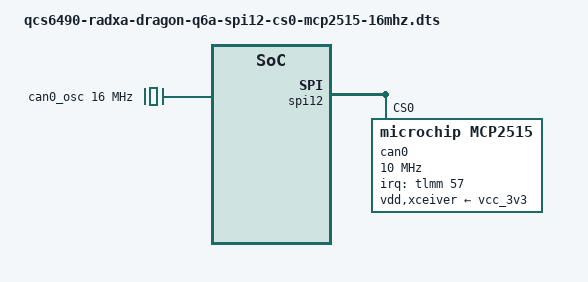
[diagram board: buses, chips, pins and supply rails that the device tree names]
// SPDX-License-Identifier: BSD-3-Clause
//
// Enable MCP2515 SPI CAN controller on SPI12 CS0 with 16 MHz external clock.
// Target: Radxa Dragon Q6A (QCS6490) + Waveshare RS485 CAN HAT (B).
//
// The 16 MHz crystal is the (B)-variant HAT's crystal. The plain
// Waveshare RS485 CAN HAT ships with a 12 MHz crystal post-Aug-2019 and
// must NOT be used on Headwaters: at 500 kbit/s the MCP2515 kernel driver
// cannot achieve the 0.875 sample point with a 12 MHz clock (10/12 TQ =
// 0.833 is the closest reachable), which produced 25–35% RX CRC errors
// in bench and vehicle testing. With 16 MHz the driver hits 14/16 TQ =
// 0.875 exactly and CAN is stable.
//
// 40-pin header mapping (Q6A → same physical pins as RPi's SPI0):
//   pin 19 MOSI → GPIO_49 (SPI12_MOSI)
//   pin 21 MISO → GPIO_48 (SPI12_MISO)
//   pin 23 SCLK → GPIO_50 (SPI12_SCLK)
//   pin 24 CE0  → GPIO_51 (SPI12_CS_0)
//   pin 22 INT  → GPIO_57 (MCP2515 interrupt, falling edge)
//
// Derived from Radxa's upstream DTSO at
//   github.com/radxa-pkg/radxa-overlays
//   arch/arm64/boot/dts/qcom/overlays/
// Vendored here (rather than relying on the radxa-overlays-dkms package) so
// that the image build is deterministic and does not require a DKMS build
// inside the qemu chroot. The two #include directives and the
// IRQ_TYPE_EDGE_FALLING macro from the upstream .dtso are inlined below as
// literal integers so this file compiles with plain `dtc -@` and no cpp pass.
//
// Inline constants (from <dt-bindings/interrupt-controller/irq.h>):
//   IRQ_TYPE_EDGE_FALLING = 2
// <dt-bindings/gpio/gpio.h> was included upstream but none of its macros
// are actually referenced in this overlay, so it is omitted here.

/dts-v1/;
/plugin/;

/ {
	metadata {
		title = "Enable MCP2515 with 16MHz external clock on SPI12 over CS0";
		compatible = "radxa,dragon-q6a";
		category = "misc";
		exclusive = "spi12", "uart12", "i2c12", "gpio48", "gpio49", "gpio50", "gpio51", "GPIO_57";
		description = "Enable MCP2515 with 16MHz external clock on SPI12 over CS0.

Provide support for Microchip MCP2515 SPI CAN controller.
Assumes 16MHz external clock (Waveshare RS485 CAN HAT (B) — the isolated
variant with TJA1051 transceiver). The plain Waveshare RS485 CAN HAT
(12 MHz crystal, SN65HVD230) is NOT compatible with this overlay and
must NOT be used on Headwaters.
Uses Pin 22 (GPIO_57) for INT.";
	};
};

&i2c12 {
	status = "disabled";
};

&uart12 {
	status = "disabled";
};

&spi12 {
	qcom,enable-gsi-dma;
	status = "okay";
	max-freq = <10000000>;
	#address-cells = <1>;
	#size-cells = <0>;

	can0: mcp2515@0 {
		compatible = "microchip,mcp2515";
		status = "okay";
		reg = <0>;
		spi-max-frequency = <10000000>;

		interrupt-parent = <&tlmm>;
		interrupts = <57 2>;   /* GPIO_57, IRQ_TYPE_EDGE_FALLING */

		clocks = <&can0_osc>;
		vdd-supply = <&vcc_3v3>;
		xceiver-supply = <&vcc_3v3>;
	};
};

&{/} {
	can0_osc: can0-osc {
		compatible = "fixed-clock";
		#clock-cells = <0>;
		clock-frequency  = <16000000>;
	};
};
